# ECC_AGGR11_ECC_AGGR register map
Vendor: Texas Instruments
Peripheral module from a debugger description file (folder J721S2).
Registers are 32-bit, access not given, reset 0x0 unless marked. A register's access mark holds for its fields unless they carry their own. Offsets are as the file gives them; lines under a group give offsets from that group; [hi:lo] are bit positions; {n}, {i} and the like mark numbered series; 'fields as' and 'values as' point back to an identical list; <NAME> marks a mode.

## ECC_AGGR11_ECC_AGGR
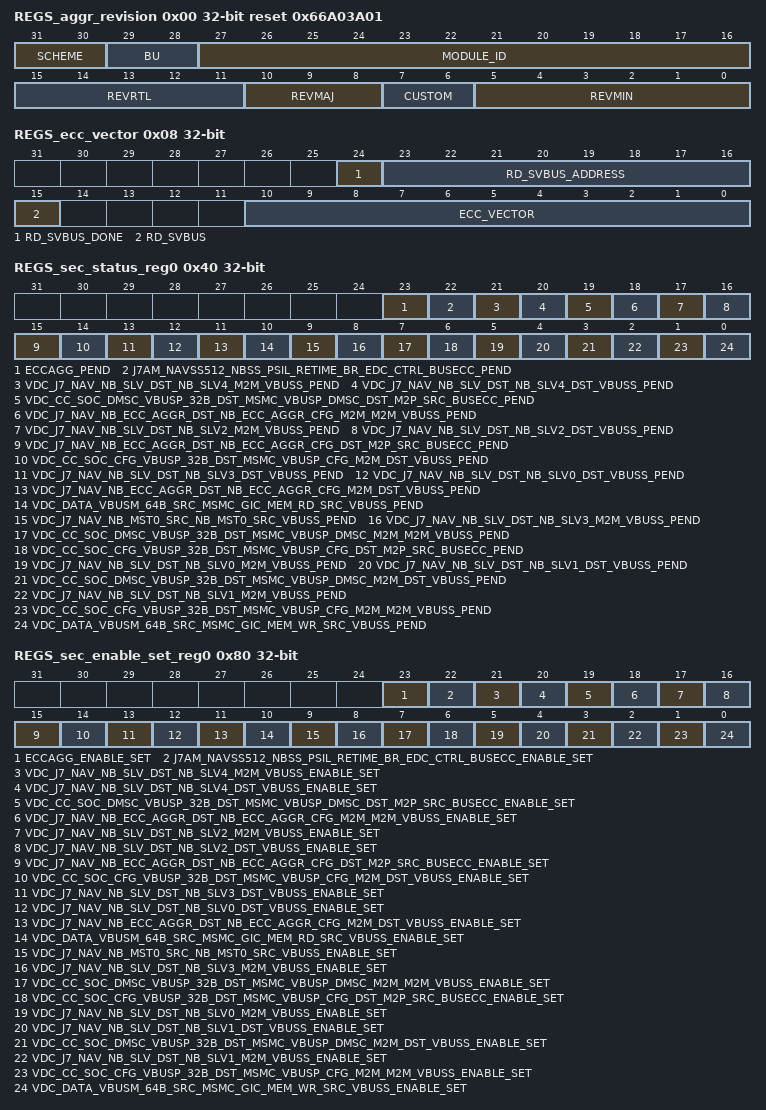
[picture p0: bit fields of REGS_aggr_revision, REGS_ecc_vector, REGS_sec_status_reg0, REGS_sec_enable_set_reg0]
0x00 REGS_aggr_revision ro reset 0x66A03A01 — Revision parameters
  [31:30] SCHEME
  [29:28] BU
  [27:16] MODULE_ID
  [15:11] REVRTL — RTL version
  [10:8] REVMAJ — Major version
  [7:6] CUSTOM — Custom version
  [5:0] REVMIN — Minor version
0x08 REGS_ecc_vector — ECC Vector Register
  [24] RD_SVBUS_DONE — Status to indicate if read on serial VBUS is complete, write of any value will clear this bit. (access R/W1TC)
  [23:16] RD_SVBUS_ADDRESS rw — Read address
  [15] RD_SVBUS — Write 1 to trigger a read on the serial VBUS (access R/W1TS)
  [10:0] ECC_VECTOR rw — Value written to select the corresponding ECC RAM for control or status
0x0C REGS_misc_status ro reset 0x18 — Misc Status
  [10:0] NUM_RAMS — Indicates the number of RAMS serviced by the ECC aggregator
0x10 REGS_reserved_svbus rw — Reference other documents that contain the ECC RAM wrapper and EDC controller serial vbus register sets.
  [31:0] DATA — Serial VBUS register data
0x3C REGS_sec_eoi_reg — EOI Register
  [0] EOI_WR — EOI Register (access R/W1TS)
0x40 REGS_sec_status_reg0 — Interrupt Status Register 0
  [23] ECCAGG_PEND — Interrupt Pending Status for eccagg_pend (access R/W1TS)
  [22] J7AM_NAVSS512_NBSS_PSIL_RETIME_BR_EDC_CTRL_BUSECC_PEND — Interrupt Pending Status for j7am_navss512_nbss_psil_retime_br_edc_ctrl_busecc_pend (access R/W1TS)
  [21] VDC_J7_NAV_NB_SLV_DST_NB_SLV4_M2M_VBUSS_PEND — Interrupt Pending Status for vdc_j7_nav_nb_slv_dst_nb_slv4_m2m_vbuss_pend (access R/W1TS)
  [20] VDC_J7_NAV_NB_SLV_DST_NB_SLV4_DST_VBUSS_PEND — Interrupt Pending Status for vdc_j7_nav_nb_slv_dst_nb_slv4_dst_vbuss_pend (access R/W1TS)
  [19] VDC_CC_SOC_DMSC_VBUSP_32B_DST_MSMC_VBUSP_DMSC_DST_M2P_SRC_BUSECC_PEND — Interrupt Pending Status for vdc_cc_soc_dmsc_vbusp_32b_dst_msmc_vbusp_dmsc_dst_m2p_src_busecc_pend (access R/W1TS)
  [18] VDC_J7_NAV_NB_ECC_AGGR_DST_NB_ECC_AGGR_CFG_M2M_M2M_VBUSS_PEND — Interrupt Pending Status for vdc_j7_nav_nb_ecc_aggr_dst_nb_ecc_aggr_cfg_m2m_m2m_vbuss_pend (access R/W1TS)
  [17] VDC_J7_NAV_NB_SLV_DST_NB_SLV2_M2M_VBUSS_PEND — Interrupt Pending Status for vdc_j7_nav_nb_slv_dst_nb_slv2_m2m_vbuss_pend (access R/W1TS)
  [16] VDC_J7_NAV_NB_SLV_DST_NB_SLV2_DST_VBUSS_PEND — Interrupt Pending Status for vdc_j7_nav_nb_slv_dst_nb_slv2_dst_vbuss_pend (access R/W1TS)
  [15] VDC_J7_NAV_NB_ECC_AGGR_DST_NB_ECC_AGGR_CFG_DST_M2P_SRC_BUSECC_PEND — Interrupt Pending Status for vdc_j7_nav_nb_ecc_aggr_dst_nb_ecc_aggr_cfg_dst_m2p_src_busecc_pend (access R/W1TS)
  [14] VDC_CC_SOC_CFG_VBUSP_32B_DST_MSMC_VBUSP_CFG_M2M_DST_VBUSS_PEND — Interrupt Pending Status for vdc_cc_soc_cfg_vbusp_32b_dst_msmc_vbusp_cfg_m2m_dst_vbuss_pend (access R/W1TS)
  [13] VDC_J7_NAV_NB_SLV_DST_NB_SLV3_DST_VBUSS_PEND — Interrupt Pending Status for vdc_j7_nav_nb_slv_dst_nb_slv3_dst_vbuss_pend (access R/W1TS)
  [12] VDC_J7_NAV_NB_SLV_DST_NB_SLV0_DST_VBUSS_PEND — Interrupt Pending Status for vdc_j7_nav_nb_slv_dst_nb_slv0_dst_vbuss_pend (access R/W1TS)
  [11] VDC_J7_NAV_NB_ECC_AGGR_DST_NB_ECC_AGGR_CFG_M2M_DST_VBUSS_PEND — Interrupt Pending Status for vdc_j7_nav_nb_ecc_aggr_dst_nb_ecc_aggr_cfg_m2m_dst_vbuss_pend (access R/W1TS)
  [10] VDC_DATA_VBUSM_64B_SRC_MSMC_GIC_MEM_RD_SRC_VBUSS_PEND — Interrupt Pending Status for vdc_data_vbusm_64b_src_msmc_gic_mem_rd_src_vbuss_pend (access R/W1TS)
  [9] VDC_J7_NAV_NB_MST0_SRC_NB_MST0_SRC_VBUSS_PEND — Interrupt Pending Status for vdc_j7_nav_nb_mst0_src_nb_mst0_src_vbuss_pend (access R/W1TS)
  [8] VDC_J7_NAV_NB_SLV_DST_NB_SLV3_M2M_VBUSS_PEND — Interrupt Pending Status for vdc_j7_nav_nb_slv_dst_nb_slv3_m2m_vbuss_pend (access R/W1TS)
  [7] VDC_CC_SOC_DMSC_VBUSP_32B_DST_MSMC_VBUSP_DMSC_M2M_M2M_VBUSS_PEND — Interrupt Pending Status for vdc_cc_soc_dmsc_vbusp_32b_dst_msmc_vbusp_dmsc_m2m_m2m_vbuss_pend (access R/W1TS)
  [6] VDC_CC_SOC_CFG_VBUSP_32B_DST_MSMC_VBUSP_CFG_DST_M2P_SRC_BUSECC_PEND — Interrupt Pending Status for vdc_cc_soc_cfg_vbusp_32b_dst_msmc_vbusp_cfg_dst_m2p_src_busecc_pend (access R/W1TS)
  [5] VDC_J7_NAV_NB_SLV_DST_NB_SLV0_M2M_VBUSS_PEND — Interrupt Pending Status for vdc_j7_nav_nb_slv_dst_nb_slv0_m2m_vbuss_pend (access R/W1TS)
  [4] VDC_J7_NAV_NB_SLV_DST_NB_SLV1_DST_VBUSS_PEND — Interrupt Pending Status for vdc_j7_nav_nb_slv_dst_nb_slv1_dst_vbuss_pend (access R/W1TS)
  [3] VDC_CC_SOC_DMSC_VBUSP_32B_DST_MSMC_VBUSP_DMSC_M2M_DST_VBUSS_PEND — Interrupt Pending Status for vdc_cc_soc_dmsc_vbusp_32b_dst_msmc_vbusp_dmsc_m2m_dst_vbuss_pend (access R/W1TS)
  [2] VDC_J7_NAV_NB_SLV_DST_NB_SLV1_M2M_VBUSS_PEND — Interrupt Pending Status for vdc_j7_nav_nb_slv_dst_nb_slv1_m2m_vbuss_pend (access R/W1TS)
  [1] VDC_CC_SOC_CFG_VBUSP_32B_DST_MSMC_VBUSP_CFG_M2M_M2M_VBUSS_PEND — Interrupt Pending Status for vdc_cc_soc_cfg_vbusp_32b_dst_msmc_vbusp_cfg_m2m_m2m_vbuss_pend (access R/W1TS)
  [0] VDC_DATA_VBUSM_64B_SRC_MSMC_GIC_MEM_WR_SRC_VBUSS_PEND — Interrupt Pending Status for vdc_data_vbusm_64b_src_msmc_gic_mem_wr_src_vbuss_pend (access R/W1TS)
0x80 REGS_sec_enable_set_reg0 — Interrupt Enable Set Register 0
  [23] ECCAGG_ENABLE_SET — Interrupt Enable Set Register for eccagg_pend (access R/W1TS)
  [22] J7AM_NAVSS512_NBSS_PSIL_RETIME_BR_EDC_CTRL_BUSECC_ENABLE_SET — Interrupt Enable Set Register for j7am_navss512_nbss_psil_retime_br_edc_ctrl_busecc_pend (access R/W1TS)
  [21] VDC_J7_NAV_NB_SLV_DST_NB_SLV4_M2M_VBUSS_ENABLE_SET — Interrupt Enable Set Register for vdc_j7_nav_nb_slv_dst_nb_slv4_m2m_vbuss_pend (access R/W1TS)
  [20] VDC_J7_NAV_NB_SLV_DST_NB_SLV4_DST_VBUSS_ENABLE_SET — Interrupt Enable Set Register for vdc_j7_nav_nb_slv_dst_nb_slv4_dst_vbuss_pend (access R/W1TS)
  [19] VDC_CC_SOC_DMSC_VBUSP_32B_DST_MSMC_VBUSP_DMSC_DST_M2P_SRC_BUSECC_ENABLE_SET — Interrupt Enable Set Register for vdc_cc_soc_dmsc_vbusp_32b_dst_msmc_vbusp_dmsc_dst_m2p_src_busecc_pend (access R/W1TS)
  [18] VDC_J7_NAV_NB_ECC_AGGR_DST_NB_ECC_AGGR_CFG_M2M_M2M_VBUSS_ENABLE_SET — Interrupt Enable Set Register for vdc_j7_nav_nb_ecc_aggr_dst_nb_ecc_aggr_cfg_m2m_m2m_vbuss_pend (access R/W1TS)
  [17] VDC_J7_NAV_NB_SLV_DST_NB_SLV2_M2M_VBUSS_ENABLE_SET — Interrupt Enable Set Register for vdc_j7_nav_nb_slv_dst_nb_slv2_m2m_vbuss_pend (access R/W1TS)
  [16] VDC_J7_NAV_NB_SLV_DST_NB_SLV2_DST_VBUSS_ENABLE_SET — Interrupt Enable Set Register for vdc_j7_nav_nb_slv_dst_nb_slv2_dst_vbuss_pend (access R/W1TS)
  [15] VDC_J7_NAV_NB_ECC_AGGR_DST_NB_ECC_AGGR_CFG_DST_M2P_SRC_BUSECC_ENABLE_SET — Interrupt Enable Set Register for vdc_j7_nav_nb_ecc_aggr_dst_nb_ecc_aggr_cfg_dst_m2p_src_busecc_pend (access R/W1TS)
  [14] VDC_CC_SOC_CFG_VBUSP_32B_DST_MSMC_VBUSP_CFG_M2M_DST_VBUSS_ENABLE_SET — Interrupt Enable Set Register for vdc_cc_soc_cfg_vbusp_32b_dst_msmc_vbusp_cfg_m2m_dst_vbuss_pend (access R/W1TS)
  [13] VDC_J7_NAV_NB_SLV_DST_NB_SLV3_DST_VBUSS_ENABLE_SET — Interrupt Enable Set Register for vdc_j7_nav_nb_slv_dst_nb_slv3_dst_vbuss_pend (access R/W1TS)
  [12] VDC_J7_NAV_NB_SLV_DST_NB_SLV0_DST_VBUSS_ENABLE_SET — Interrupt Enable Set Register for vdc_j7_nav_nb_slv_dst_nb_slv0_dst_vbuss_pend (access R/W1TS)
  [11] VDC_J7_NAV_NB_ECC_AGGR_DST_NB_ECC_AGGR_CFG_M2M_DST_VBUSS_ENABLE_SET — Interrupt Enable Set Register for vdc_j7_nav_nb_ecc_aggr_dst_nb_ecc_aggr_cfg_m2m_dst_vbuss_pend (access R/W1TS)
  [10] VDC_DATA_VBUSM_64B_SRC_MSMC_GIC_MEM_RD_SRC_VBUSS_ENABLE_SET — Interrupt Enable Set Register for vdc_data_vbusm_64b_src_msmc_gic_mem_rd_src_vbuss_pend (access R/W1TS)
  [9] VDC_J7_NAV_NB_MST0_SRC_NB_MST0_SRC_VBUSS_ENABLE_SET — Interrupt Enable Set Register for vdc_j7_nav_nb_mst0_src_nb_mst0_src_vbuss_pend (access R/W1TS)
  [8] VDC_J7_NAV_NB_SLV_DST_NB_SLV3_M2M_VBUSS_ENABLE_SET — Interrupt Enable Set Register for vdc_j7_nav_nb_slv_dst_nb_slv3_m2m_vbuss_pend (access R/W1TS)
  [7] VDC_CC_SOC_DMSC_VBUSP_32B_DST_MSMC_VBUSP_DMSC_M2M_M2M_VBUSS_ENABLE_SET — Interrupt Enable Set Register for vdc_cc_soc_dmsc_vbusp_32b_dst_msmc_vbusp_dmsc_m2m_m2m_vbuss_pend (access R/W1TS)
  [6] VDC_CC_SOC_CFG_VBUSP_32B_DST_MSMC_VBUSP_CFG_DST_M2P_SRC_BUSECC_ENABLE_SET — Interrupt Enable Set Register for vdc_cc_soc_cfg_vbusp_32b_dst_msmc_vbusp_cfg_dst_m2p_src_busecc_pend (access R/W1TS)
  [5] VDC_J7_NAV_NB_SLV_DST_NB_SLV0_M2M_VBUSS_ENABLE_SET — Interrupt Enable Set Register for vdc_j7_nav_nb_slv_dst_nb_slv0_m2m_vbuss_pend (access R/W1TS)
  [4] VDC_J7_NAV_NB_SLV_DST_NB_SLV1_DST_VBUSS_ENABLE_SET — Interrupt Enable Set Register for vdc_j7_nav_nb_slv_dst_nb_slv1_dst_vbuss_pend (access R/W1TS)
  [3] VDC_CC_SOC_DMSC_VBUSP_32B_DST_MSMC_VBUSP_DMSC_M2M_DST_VBUSS_ENABLE_SET — Interrupt Enable Set Register for vdc_cc_soc_dmsc_vbusp_32b_dst_msmc_vbusp_dmsc_m2m_dst_vbuss_pend (access R/W1TS)
  [2] VDC_J7_NAV_NB_SLV_DST_NB_SLV1_M2M_VBUSS_ENABLE_SET — Interrupt Enable Set Register for vdc_j7_nav_nb_slv_dst_nb_slv1_m2m_vbuss_pend (access R/W1TS)
  [1] VDC_CC_SOC_CFG_VBUSP_32B_DST_MSMC_VBUSP_CFG_M2M_M2M_VBUSS_ENABLE_SET — Interrupt Enable Set Register for vdc_cc_soc_cfg_vbusp_32b_dst_msmc_vbusp_cfg_m2m_m2m_vbuss_pend (access R/W1TS)
  [0] VDC_DATA_VBUSM_64B_SRC_MSMC_GIC_MEM_WR_SRC_VBUSS_ENABLE_SET — Interrupt Enable Set Register for vdc_data_vbusm_64b_src_msmc_gic_mem_wr_src_vbuss_pend (access R/W1TS)
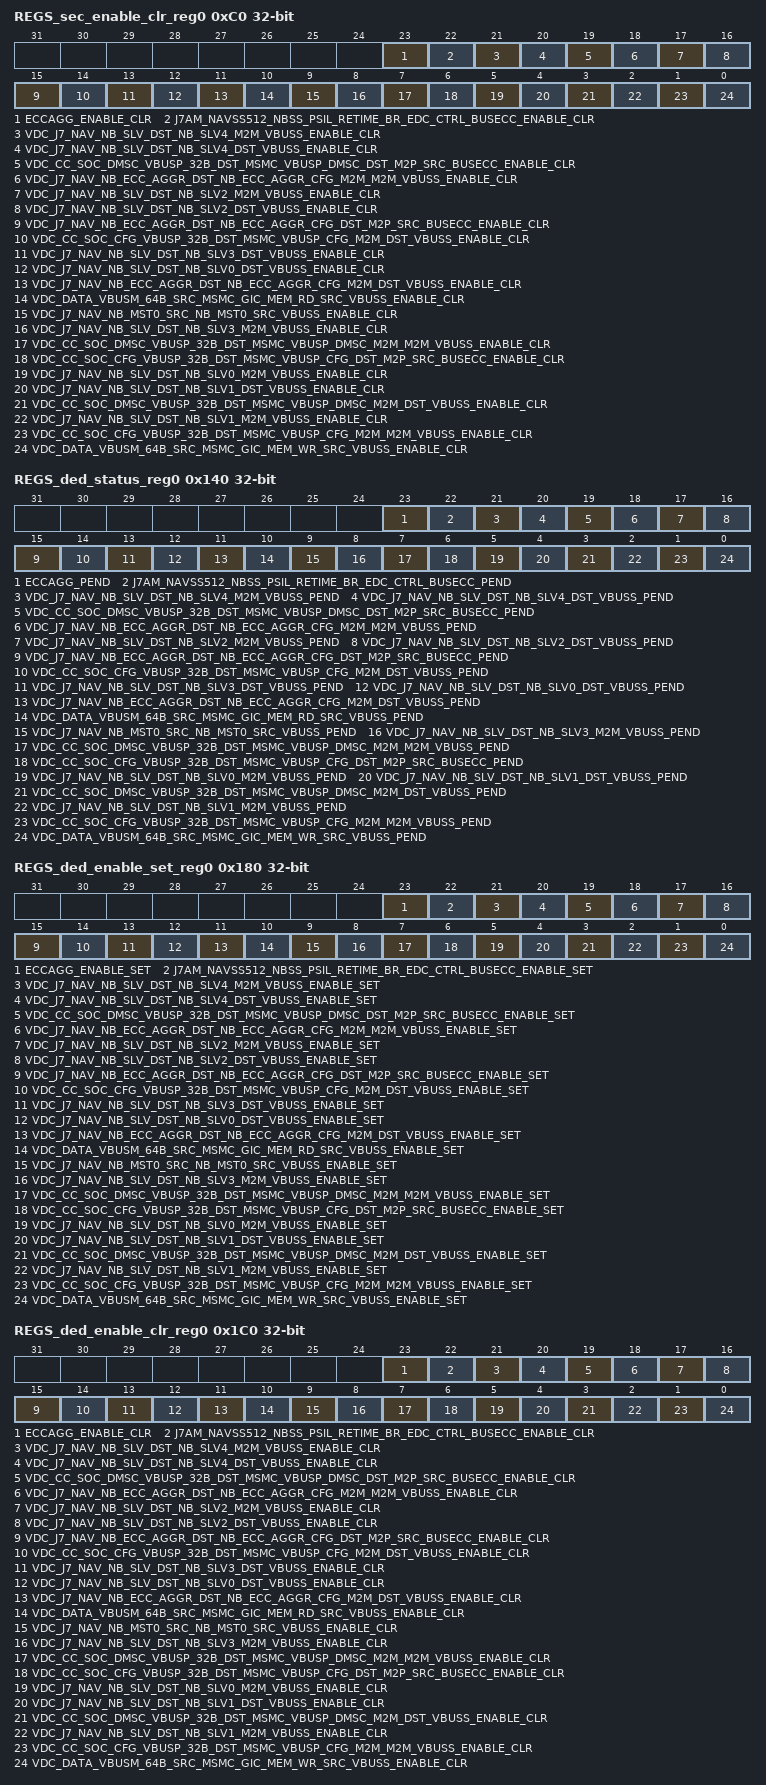
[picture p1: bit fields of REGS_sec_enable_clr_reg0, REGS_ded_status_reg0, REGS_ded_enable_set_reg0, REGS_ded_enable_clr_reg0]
0xC0 REGS_sec_enable_clr_reg0 — Interrupt Enable Clear Register 0
  [23] ECCAGG_ENABLE_CLR — Interrupt Enable Clear Register for eccagg_pend (access R/W1TC)
  [22] J7AM_NAVSS512_NBSS_PSIL_RETIME_BR_EDC_CTRL_BUSECC_ENABLE_CLR — Interrupt Enable Clear Register for j7am_navss512_nbss_psil_retime_br_edc_ctrl_busecc_pend (access R/W1TC)
  [21] VDC_J7_NAV_NB_SLV_DST_NB_SLV4_M2M_VBUSS_ENABLE_CLR — Interrupt Enable Clear Register for vdc_j7_nav_nb_slv_dst_nb_slv4_m2m_vbuss_pend (access R/W1TC)
  [20] VDC_J7_NAV_NB_SLV_DST_NB_SLV4_DST_VBUSS_ENABLE_CLR — Interrupt Enable Clear Register for vdc_j7_nav_nb_slv_dst_nb_slv4_dst_vbuss_pend (access R/W1TC)
  [19] VDC_CC_SOC_DMSC_VBUSP_32B_DST_MSMC_VBUSP_DMSC_DST_M2P_SRC_BUSECC_ENABLE_CLR — Interrupt Enable Clear Register for vdc_cc_soc_dmsc_vbusp_32b_dst_msmc_vbusp_dmsc_dst_m2p_src_busecc_pend (access R/W1TC)
  [18] VDC_J7_NAV_NB_ECC_AGGR_DST_NB_ECC_AGGR_CFG_M2M_M2M_VBUSS_ENABLE_CLR — Interrupt Enable Clear Register for vdc_j7_nav_nb_ecc_aggr_dst_nb_ecc_aggr_cfg_m2m_m2m_vbuss_pend (access R/W1TC)
  [17] VDC_J7_NAV_NB_SLV_DST_NB_SLV2_M2M_VBUSS_ENABLE_CLR — Interrupt Enable Clear Register for vdc_j7_nav_nb_slv_dst_nb_slv2_m2m_vbuss_pend (access R/W1TC)
  [16] VDC_J7_NAV_NB_SLV_DST_NB_SLV2_DST_VBUSS_ENABLE_CLR — Interrupt Enable Clear Register for vdc_j7_nav_nb_slv_dst_nb_slv2_dst_vbuss_pend (access R/W1TC)
  [15] VDC_J7_NAV_NB_ECC_AGGR_DST_NB_ECC_AGGR_CFG_DST_M2P_SRC_BUSECC_ENABLE_CLR — Interrupt Enable Clear Register for vdc_j7_nav_nb_ecc_aggr_dst_nb_ecc_aggr_cfg_dst_m2p_src_busecc_pend (access R/W1TC)
  [14] VDC_CC_SOC_CFG_VBUSP_32B_DST_MSMC_VBUSP_CFG_M2M_DST_VBUSS_ENABLE_CLR — Interrupt Enable Clear Register for vdc_cc_soc_cfg_vbusp_32b_dst_msmc_vbusp_cfg_m2m_dst_vbuss_pend (access R/W1TC)
  [13] VDC_J7_NAV_NB_SLV_DST_NB_SLV3_DST_VBUSS_ENABLE_CLR — Interrupt Enable Clear Register for vdc_j7_nav_nb_slv_dst_nb_slv3_dst_vbuss_pend (access R/W1TC)
  [12] VDC_J7_NAV_NB_SLV_DST_NB_SLV0_DST_VBUSS_ENABLE_CLR — Interrupt Enable Clear Register for vdc_j7_nav_nb_slv_dst_nb_slv0_dst_vbuss_pend (access R/W1TC)
  [11] VDC_J7_NAV_NB_ECC_AGGR_DST_NB_ECC_AGGR_CFG_M2M_DST_VBUSS_ENABLE_CLR — Interrupt Enable Clear Register for vdc_j7_nav_nb_ecc_aggr_dst_nb_ecc_aggr_cfg_m2m_dst_vbuss_pend (access R/W1TC)
  [10] VDC_DATA_VBUSM_64B_SRC_MSMC_GIC_MEM_RD_SRC_VBUSS_ENABLE_CLR — Interrupt Enable Clear Register for vdc_data_vbusm_64b_src_msmc_gic_mem_rd_src_vbuss_pend (access R/W1TC)
  [9] VDC_J7_NAV_NB_MST0_SRC_NB_MST0_SRC_VBUSS_ENABLE_CLR — Interrupt Enable Clear Register for vdc_j7_nav_nb_mst0_src_nb_mst0_src_vbuss_pend (access R/W1TC)
  [8] VDC_J7_NAV_NB_SLV_DST_NB_SLV3_M2M_VBUSS_ENABLE_CLR — Interrupt Enable Clear Register for vdc_j7_nav_nb_slv_dst_nb_slv3_m2m_vbuss_pend (access R/W1TC)
  [7] VDC_CC_SOC_DMSC_VBUSP_32B_DST_MSMC_VBUSP_DMSC_M2M_M2M_VBUSS_ENABLE_CLR — Interrupt Enable Clear Register for vdc_cc_soc_dmsc_vbusp_32b_dst_msmc_vbusp_dmsc_m2m_m2m_vbuss_pend (access R/W1TC)
  [6] VDC_CC_SOC_CFG_VBUSP_32B_DST_MSMC_VBUSP_CFG_DST_M2P_SRC_BUSECC_ENABLE_CLR — Interrupt Enable Clear Register for vdc_cc_soc_cfg_vbusp_32b_dst_msmc_vbusp_cfg_dst_m2p_src_busecc_pend (access R/W1TC)
  [5] VDC_J7_NAV_NB_SLV_DST_NB_SLV0_M2M_VBUSS_ENABLE_CLR — Interrupt Enable Clear Register for vdc_j7_nav_nb_slv_dst_nb_slv0_m2m_vbuss_pend (access R/W1TC)
  [4] VDC_J7_NAV_NB_SLV_DST_NB_SLV1_DST_VBUSS_ENABLE_CLR — Interrupt Enable Clear Register for vdc_j7_nav_nb_slv_dst_nb_slv1_dst_vbuss_pend (access R/W1TC)
  [3] VDC_CC_SOC_DMSC_VBUSP_32B_DST_MSMC_VBUSP_DMSC_M2M_DST_VBUSS_ENABLE_CLR — Interrupt Enable Clear Register for vdc_cc_soc_dmsc_vbusp_32b_dst_msmc_vbusp_dmsc_m2m_dst_vbuss_pend (access R/W1TC)
  [2] VDC_J7_NAV_NB_SLV_DST_NB_SLV1_M2M_VBUSS_ENABLE_CLR — Interrupt Enable Clear Register for vdc_j7_nav_nb_slv_dst_nb_slv1_m2m_vbuss_pend (access R/W1TC)
  [1] VDC_CC_SOC_CFG_VBUSP_32B_DST_MSMC_VBUSP_CFG_M2M_M2M_VBUSS_ENABLE_CLR — Interrupt Enable Clear Register for vdc_cc_soc_cfg_vbusp_32b_dst_msmc_vbusp_cfg_m2m_m2m_vbuss_pend (access R/W1TC)
  [0] VDC_DATA_VBUSM_64B_SRC_MSMC_GIC_MEM_WR_SRC_VBUSS_ENABLE_CLR — Interrupt Enable Clear Register for vdc_data_vbusm_64b_src_msmc_gic_mem_wr_src_vbuss_pend (access R/W1TC)
0x13C REGS_ded_eoi_reg — EOI Register
  [0] EOI_WR — EOI Register (access R/W1TS)
0x140 REGS_ded_status_reg0 — Interrupt Status Register 0
  fields as REGS_sec_status_reg0
0x180 REGS_ded_enable_set_reg0 — Interrupt Enable Set Register 0
  fields as REGS_sec_enable_set_reg0
0x1C0 REGS_ded_enable_clr_reg0 — Interrupt Enable Clear Register 0
  fields as REGS_sec_enable_clr_reg0
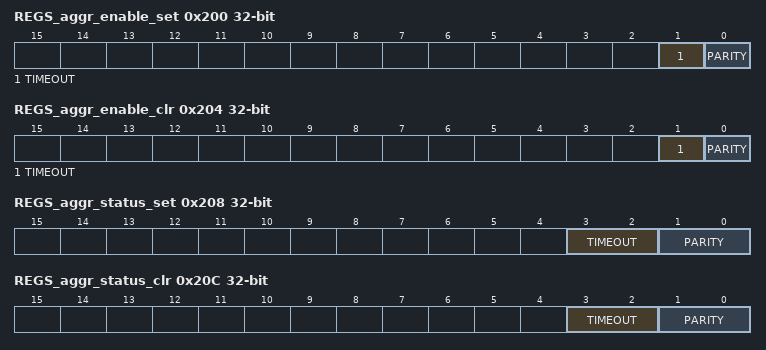
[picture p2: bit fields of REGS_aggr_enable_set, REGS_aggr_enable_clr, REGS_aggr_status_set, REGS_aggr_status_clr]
0x200 REGS_aggr_enable_set — AGGR interrupt enable set Register
  [1] TIMEOUT — interrupt enable set for svbus timeout errors (access R/W1TS)
  [0] PARITY — interrupt enable set for parity errors (access R/W1TS)
0x204 REGS_aggr_enable_clr — AGGR interrupt enable clear Register
  [1] TIMEOUT — interrupt enable clear for svbus timeout errors (access R/W1TC)
  [0] PARITY — interrupt enable clear for parity errors (access R/W1TC)
0x208 REGS_aggr_status_set — AGGR interrupt status set Register
  [3:2] TIMEOUT — interrupt status set for svbus timeout errors (access R/WI)
  [1:0] PARITY — interrupt status set for parity errors (access R/WI)
0x20C REGS_aggr_status_clr — AGGR interrupt status clear Register
  [3:2] TIMEOUT — interrupt status clear for svbus timeout errors (access R/WD)
  [1:0] PARITY — interrupt status clear for parity errors (access R/WD)
